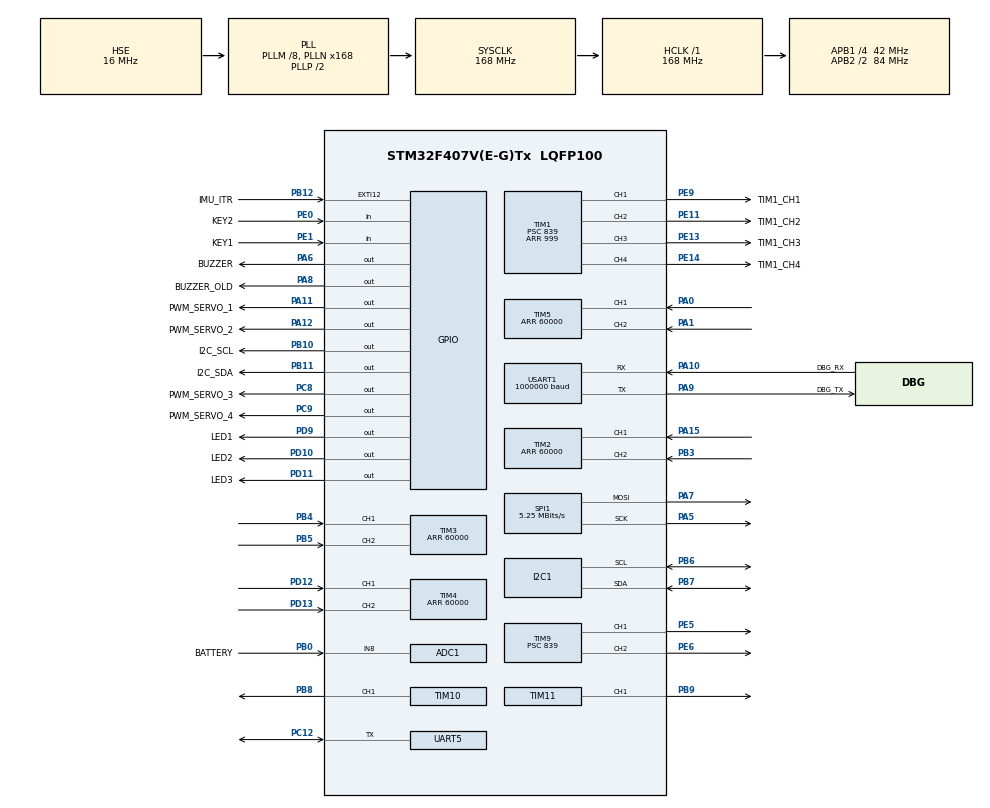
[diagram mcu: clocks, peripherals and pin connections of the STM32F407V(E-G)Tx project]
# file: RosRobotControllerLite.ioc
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ADC1.Channel-4\#ChannelRegularConversion=ADC_CHANNEL_VREFINT
ADC1.Channel-5\#ChannelRegularConversion=ADC_CHANNEL_8
ADC1.ClockPrescaler=ADC_CLOCK_SYNC_PCLK_DIV8
ADC1.ContinuousConvMode=DISABLE
ADC1.EOCSelection=ADC_EOC_SEQ_CONV
ADC1.NbrOfConversion=2
ADC1.NbrOfConversionFlag=1
ADC1.Rank-4\#ChannelRegularConversion=1
ADC1.Rank-5\#ChannelRegularConversion=2
ADC1.SamplingTime-4\#ChannelRegularConversion=ADC_SAMPLETIME_480CYCLES
ADC1.SamplingTime-5\#ChannelRegularConversion=ADC_SAMPLETIME_480CYCLES
ADC1.master=1
Dma.ADC1.0.Direction=DMA_PERIPH_TO_MEMORY
Dma.ADC1.0.FIFOMode=DMA_FIFOMODE_DISABLE
Dma.ADC1.0.Instance=DMA2_Stream0
Dma.ADC1.0.MemDataAlignment=DMA_MDATAALIGN_HALFWORD
Dma.ADC1.0.MemInc=DMA_MINC_ENABLE
Dma.ADC1.0.Mode=DMA_CIRCULAR
Dma.ADC1.0.PeriphDataAlignment=DMA_PDATAALIGN_HALFWORD
Dma.ADC1.0.PeriphInc=DMA_PINC_DISABLE
Dma.ADC1.0.Priority=DMA_PRIORITY_LOW
Dma.Request0=ADC1
Dma.Request1=USART1_RX
Dma.Request2=USART1_TX
Dma.Request3=SPI1_TX
Dma.SPI1_TX.3.Direction=DMA_MEMORY_TO_PERIPH
Dma.SPI1_TX.3.FIFOMode=DMA_FIFOMODE_DISABLE
Dma.SPI1_TX.3.Instance=DMA2_Stream3
Dma.SPI1_TX.3.MemDataAlignment=DMA_MDATAALIGN_BYTE
Dma.SPI1_TX.3.MemInc=DMA_MINC_ENABLE
Dma.SPI1_TX.3.Mode=DMA_NORMAL
Dma.SPI1_TX.3.PeriphDataAlignment=DMA_PDATAALIGN_BYTE
Dma.SPI1_TX.3.PeriphInc=DMA_PINC_DISABLE
Dma.SPI1_TX.3.Priority=DMA_PRIORITY_MEDIUM
Dma.USART1_RX.1.Direction=DMA_PERIPH_TO_MEMORY
Dma.USART1_RX.1.FIFOMode=DMA_FIFOMODE_DISABLE
Dma.USART1_RX.1.Instance=DMA2_Stream2
Dma.USART1_RX.1.MemDataAlignment=DMA_MDATAALIGN_BYTE
Dma.USART1_RX.1.MemInc=DMA_MINC_ENABLE
Dma.USART1_RX.1.Mode=DMA_NORMAL
Dma.USART1_RX.1.PeriphDataAlignment=DMA_PDATAALIGN_BYTE
Dma.USART1_RX.1.PeriphInc=DMA_PINC_DISABLE
Dma.USART1_RX.1.Priority=DMA_PRIORITY_HIGH
Dma.USART1_TX.2.Direction=DMA_MEMORY_TO_PERIPH
Dma.USART1_TX.2.FIFOMode=DMA_FIFOMODE_DISABLE
Dma.USART1_TX.2.Instance=DMA2_Stream7
Dma.USART1_TX.2.MemDataAlignment=DMA_MDATAALIGN_BYTE
Dma.USART1_TX.2.MemInc=DMA_MINC_ENABLE
Dma.USART1_TX.2.Mode=DMA_NORMAL
Dma.USART1_TX.2.PeriphDataAlignment=DMA_PDATAALIGN_BYTE
Dma.USART1_TX.2.PeriphInc=DMA_PINC_DISABLE
Dma.USART1_TX.2.Priority=DMA_PRIORITY_MEDIUM
FREERTOS.BinarySemaphores01=packet_tx_idle,Static,packet_tx_ControlBlock;packet_rx_not_empty,Static,packet_rx_not_emptyControlBlock;mpu6050_data_ready,Static,mpu6050_data_readyControlBlock;spi_tx_finished,Static,spi_tx_finishedControlBlock;serial_servo_rx_complete,Dynamic,NULL
FREERTOS.INCLUDE_vTaskCleanUpResources=1
FREERTOS.INCLUDE_xEventGroupSetBitFromISR=1
FREERTOS.Mutexes01=oled_mutex,Dynamic,NULL
FREERTOS.Queues01=packet_tx_queue,64,void*,0,Static,packet_tx_queueBuffer,packet_tx_queueControlBlock;moving_ctrl_queue,32,char,0,Static,moving_ctrl_queueBuffer,moving_ctrl_queueControlBlock
FREERTOS.Tasks01=defaultTask,16,256,StartDefaultTask,Default,NULL,Dynamic,NULL,NULL;imu_task,32,256,imu_task_entry,As weak,NULL,Dynamic,NULL,NULL;packet_tx_task,24,256,packet_tx_task_entry,As weak,NULL,Dynamic,NULL,NULL;packet_rx_task,24,256,packet_rx_task_entry,As weak,NULL,Dynamic,NULL,NULL;gui_task,8,1500,gui_task_entry,As weak,NULL,Dynamic,NULL,NULL;app_task,24,512,app_task_entry,As weak,NULL,Dynamic,NULL,NULL;oled_task,16,256,oled_task_entry,As weak,NULL,Dynamic,NULL,NULL
FREERTOS.Timers01=button_timer,button_timer_callback,osTimerPeriodic,As weak,NULL,Static,button_timerControlBlock;led_timer,led_timer_callback,osTimerPeriodic,As weak,NULL,Static,led_timerControlBlock;buzzer_timer,buzzer_timer_callback,osTimerPeriodic,As weak,NULL,Static,buzzer_timerControlBlock;battery_check_timer,battery_check_timer_callback,osTimerPeriodic,As weak,NULL,Static,battery_check_timerControlBlock
FREERTOS.configENABLE_FPU=1
FREERTOS.configTIMER_QUEUE_LENGTH=10
FREERTOS.configTIMER_TASK_STACK_DEPTH=6144
FREERTOS.configTOTAL_HEAP_SIZE=20480
FREERTOS.configUSE_IDLE_HOOK=1
FREERTOS.configUSE_NEWLIB_REENTRANT=0
FREERTOS.configUSE_TICK_HOOK=1
IWDG.Prescaler=IWDG_PRESCALER_32
IWDG.Reload=19
Mcu.Family=STM32F4
Mcu.Name=STM32F407V(E-G)Tx
Mcu.Package=LQFP100
NVIC.DMA2_Stream2_IRQn=true\:5\:0\:false\:false\:true\:true\:true\:true\:true
NVIC.DMA2_Stream3_IRQn=true\:5\:0\:false\:false\:true\:true\:true\:true\:true
NVIC.DMA2_Stream7_IRQn=true\:5\:0\:false\:false\:true\:true\:true\:true\:true
NVIC.EXTI15_10_IRQn=true\:5\:0\:false\:true\:true\:3\:true\:true\:false\:true
NVIC.PriorityGroup=NVIC_PRIORITYGROUP_4
NVIC.SPI1_IRQn=true\:5\:0\:false\:false\:true\:true\:true\:true\:true
NVIC.TIM2_IRQn=true\:5\:0\:false\:true\:true\:1\:true\:true\:false\:true
NVIC.TIM3_IRQn=true\:5\:0\:false\:true\:true\:2\:true\:true\:false\:true
NVIC.TIM4_IRQn=true\:5\:0\:false\:false\:true\:true\:true\:false\:true
NVIC.TIM5_IRQn=true\:5\:0\:false\:true\:true\:6\:true\:true\:false\:true
NVIC.TIM7_IRQn=true\:5\:0\:false\:true\:true\:7\:true\:true\:false\:true
NVIC.TIM8_BRK_TIM12_IRQn=true\:5\:0\:false\:true\:true\:4\:true\:true\:false\:true
NVIC.TIM8_TRG_COM_TIM14_IRQn=true\:15\:0\:true\:false\:true\:false\:false\:true\:true
NVIC.TIM8_UP_TIM13_IRQn=true\:5\:0\:false\:true\:true\:5\:true\:true\:false\:true
NVIC.TimeBase=TIM8_TRG_COM_TIM14_IRQn
NVIC.TimeBaseIP=TIM14
NVIC.UART5_IRQn=true\:5\:0\:false\:false\:true\:true\:true\:true\:true
NVIC.USART1_IRQn=true\:5\:0\:true\:false\:true\:true\:true\:true\:true
PA0-WKUP.GPIO_PuPd=GPIO_PULLUP
PA0-WKUP.GPIO_Speed=GPIO_SPEED_FREQ_VERY_HIGH
PA0-WKUP.Signal=S_TIM5_CH1
PA1.GPIO_PuPd=GPIO_PULLUP
PA1.GPIO_Speed=GPIO_SPEED_FREQ_VERY_HIGH
PA1.Signal=S_TIM5_CH2
PA10.GPIO_Label=DBG_RX
PA10.Mode=Asynchronous
PA10.Signal=USART1_RX
PA11.GPIO_Label=PWM_SERVO_1
PA11.GPIO_Speed=GPIO_SPEED_FREQ_HIGH
PA11.PinState=GPIO_PIN_RESET
PA11.Signal=GPIO_Output
PA12.GPIO_Label=PWM_SERVO_2
PA12.GPIO_Speed=GPIO_SPEED_FREQ_HIGH
PA12.Signal=GPIO_Output
PA13.Signal=SYS_JTMS-SWDIO
PA14.Signal=SYS_JTCK-SWCLK
PA15.GPIO_PuPd=GPIO_PULLUP
PA15.GPIO_Speed=GPIO_SPEED_FREQ_VERY_HIGH
PA15.Signal=S_TIM2_CH1_ETR
PA5.GPIO_Speed=GPIO_SPEED_FREQ_MEDIUM
PA5.Mode=TX_Only_Simplex_Unidirect_Master
PA5.Signal=SPI1_SCK
PA6.GPIO_Label=BUZZER
PA6.GPIO_Speed=GPIO_SPEED_FREQ_VERY_HIGH
PA6.PinState=GPIO_PIN_RESET
PA6.Signal=GPIO_Output
PA7.GPIO_PuPd=GPIO_PULLUP
PA7.GPIO_Speed=GPIO_SPEED_FREQ_MEDIUM
PA7.Mode=TX_Only_Simplex_Unidirect_Master
PA7.Signal=SPI1_MOSI
PA8.GPIO_Label=BUZZER_OLD
PA8.GPIO_Speed=GPIO_SPEED_FREQ_VERY_HIGH
PA8.PinState=GPIO_PIN_RESET
PA8.Signal=GPIO_Output
PA9.GPIO_Label=DBG_TX
PA9.Mode=Asynchronous
PA9.Signal=USART1_TX
PB0.GPIO_Label=BATTERY
PB0.Signal=ADCx_IN8
PB10.GPIO_Label=I2C_SCL
PB10.Signal=GPIO_Output
PB11.GPIO_Label=I2C_SDA
PB11.Signal=GPIO_Output
PB12.GPIO_Label=IMU_ITR
PB12.GPIO_ModeDefaultEXTI=GPIO_MODE_IT_RISING
PB12.GPIO_PuPd=GPIO_PULLDOWN
PB12.Signal=GPXTI12
PB3.GPIO_PuPd=GPIO_PULLUP
PB3.GPIO_Speed=GPIO_SPEED_FREQ_VERY_HIGH
PB3.Signal=S_TIM2_CH2
PB4.GPIO_Speed=GPIO_SPEED_FREQ_VERY_HIGH
PB4.Signal=S_TIM3_CH1
PB5.GPIO_Speed=GPIO_SPEED_FREQ_VERY_HIGH
PB5.Signal=S_TIM3_CH2
PB6.GPIO_Pu=GPIO_PULLUP
PB6.Mode=I2C
PB6.Signal=I2C1_SCL
PB7.GPIO_Pu=GPIO_PULLUP
PB7.Mode=I2C
PB7.Signal=I2C1_SDA
PB8.Signal=S_TIM10_CH1
PB9.GPIO_Speed=GPIO_SPEED_FREQ_HIGH
PB9.Signal=S_TIM11_CH1
PC12.Mode=Half_duplex(single_wire_mode)
PC12.Signal=UART5_TX
PC8.GPIO_Label=PWM_SERVO_3
PC8.GPIO_Speed=GPIO_SPEED_FREQ_LOW
PC8.PinState=GPIO_PIN_SET
PC8.Signal=GPIO_Output
PC9.GPIO_Label=PWM_SERVO_4
PC9.GPIO_Speed=GPIO_SPEED_FREQ_HIGH
PC9.Signal=GPIO_Output
PD10.GPIO_Label=LED2
PD10.GPIO_Speed=GPIO_SPEED_FREQ_MEDIUM
PD10.PinState=GPIO_PIN_SET
PD10.Signal=GPIO_Output
PD11.GPIO_Label=LED3
PD11.GPIO_Speed=GPIO_SPEED_FREQ_MEDIUM
PD11.PinState=GPIO_PIN_RESET
PD11.Signal=GPIO_Output
PD12.GPIO_PuPd=GPIO_NOPULL
PD12.GPIO_Speed=GPIO_SPEED_FREQ_VERY_HIGH
PD12.Signal=S_TIM4_CH1
PD13.GPIO_PuPd=GPIO_NOPULL
PD13.GPIO_Speed=GPIO_SPEED_FREQ_VERY_HIGH
PD13.Signal=S_TIM4_CH2
PD9.GPIO_Label=LED1
PD9.GPIO_Speed=GPIO_SPEED_FREQ_MEDIUM
PD9.PinState=GPIO_PIN_SET
PD9.Signal=GPIO_Output
PE0.GPIO_Label=KEY2
PE0.Signal=GPIO_Input
PE1.GPIO_Label=KEY1
PE1.Signal=GPIO_Input
PE11.GPIO_Label=TIM1_CH2
PE11.GPIO_Speed=GPIO_SPEED_FREQ_HIGH
PE11.Signal=S_TIM1_CH2
PE13.GPIO_Label=TIM1_CH3
PE13.GPIO_Speed=GPIO_SPEED_FREQ_HIGH
PE13.Signal=S_TIM1_CH3
PE14.GPIO_Label=TIM1_CH4
PE14.GPIO_Speed=GPIO_SPEED_FREQ_HIGH
PE14.Signal=S_TIM1_CH4
PE5.Signal=S_TIM9_CH1
PE6.Signal=S_TIM9_CH2
PE9.GPIO_Label=TIM1_CH1
PE9.GPIO_Speed=GPIO_SPEED_FREQ_HIGH
PE9.Signal=S_TIM1_CH1
PH0-OSC_IN.Mode=HSE-External-Oscillator
PH0-OSC_IN.Signal=RCC_OSC_IN
PH1-OSC_OUT.Mode=HSE-External-Oscillator
PH1-OSC_OUT.Signal=RCC_OSC_OUT
ProjectManager.HeapSize=0x200
ProjectManager.StackSize=0x600
ProjectManager.TargetToolchain=STM32CubeIDE
RCC.48MHZClocksFreq_Value=48000000
RCC.AHBFreq_Value=168000000
RCC.APB1CLKDivider=RCC_HCLK_DIV4
RCC.APB1Freq_Value=42000000
RCC.APB1TimFreq_Value=84000000
RCC.APB2CLKDivider=RCC_HCLK_DIV2
RCC.APB2Freq_Value=84000000
RCC.APB2TimFreq_Value=168000000
RCC.CortexFreq_Value=168000000
RCC.EnbaleCSS=true
RCC.HCLKFreq_Value=168000000
RCC.HSE_VALUE=16000000
RCC.HSI_VALUE=16000000
RCC.LSE_VALUE=32768
RCC.PLLM=8
RCC.PLLN=168
RCC.PLLQ=7
RCC.PLLSourceVirtual=RCC_PLLSOURCE_HSE
RCC.SYSCLKFreq_VALUE=168000000
RCC.SYSCLKSource=RCC_SYSCLKSOURCE_PLLCLK
RCC.VCOOutputFreq_Value=336000000
SH.ADCx_IN8.0=ADC1_IN8,IN8
SH.S_TIM10_CH1.0=TIM10_CH1,PWM Generation1 CH1
SH.S_TIM11_CH1.0=TIM11_CH1,PWM Generation1 CH1
SH.S_TIM1_CH1.0=TIM1_CH1,PWM Generation1 CH1
SH.S_TIM1_CH2.0=TIM1_CH2,PWM Generation2 CH2
SH.S_TIM1_CH3.0=TIM1_CH3,PWM Generation3 CH3
SH.S_TIM1_CH4.0=TIM1_CH4,PWM Generation4 CH4
SH.S_TIM2_CH1_ETR.0=TIM2_CH1,Encoder_Interface
SH.S_TIM2_CH2.0=TIM2_CH2,Encoder_Interface
SH.S_TIM3_CH1.0=TIM3_CH1,Encoder_Interface
SH.S_TIM3_CH2.0=TIM3_CH2,Encoder_Interface
SH.S_TIM4_CH1.0=TIM4_CH1,Encoder_Interface
SH.S_TIM4_CH2.0=TIM4_CH2,Encoder_Interface
SH.S_TIM5_CH1.0=TIM5_CH1,Encoder_Interface
SH.S_TIM5_CH2.0=TIM5_CH2,Encoder_Interface
SH.S_TIM9_CH1.0=TIM9_CH1,PWM Generation1 CH1
SH.S_TIM9_CH2.0=TIM9_CH2,PWM Generation2 CH2
SPI1.BaudRatePrescaler=SPI_BAUDRATEPRESCALER_16
SPI1.CLKPolarity=SPI_POLARITY_LOW
SPI1.CalculateBaudRate=5.25 MBits/s
SPI1.Direction=SPI_DIRECTION_2LINES
SPI1.Mode=SPI_MODE_MASTER
SPI1.VirtualType=VM_MASTER
TIM1.AutoReloadPreload=TIM_AUTORELOAD_PRELOAD_ENABLE
TIM1.Channel-PWM\ Generation1\ CH1=TIM_CHANNEL_1
TIM1.Channel-PWM\ Generation2\ CH2=TIM_CHANNEL_2
TIM1.Channel-PWM\ Generation3\ CH3=TIM_CHANNEL_3
TIM1.Channel-PWM\ Generation4\ CH4=TIM_CHANNEL_4
TIM1.OCFastMode_PWM-PWM\ Generation1\ CH1=TIM_OCFAST_ENABLE
TIM1.OCFastMode_PWM-PWM\ Generation2\ CH2=TIM_OCFAST_ENABLE
TIM1.OCFastMode_PWM-PWM\ Generation3\ CH3=TIM_OCFAST_ENABLE
TIM1.OCFastMode_PWM-PWM\ Generation4\ CH4=TIM_OCFAST_ENABLE
TIM1.Period=999
TIM1.Prescaler=839
TIM1.Pulse-PWM\ Generation1\ CH1=0
TIM1.Pulse-PWM\ Generation2\ CH2=0
TIM1.Pulse-PWM\ Generation3\ CH3=0
TIM1.Pulse-PWM\ Generation4\ CH4=0
TIM10.AutoReloadPreload=TIM_AUTORELOAD_PRELOAD_ENABLE
TIM10.Channel=TIM_CHANNEL_1
TIM10.OCFastMode_PWM=TIM_OCFAST_ENABLE
TIM10.Period=999
TIM10.Prescaler=839
TIM11.AutoReloadPreload=TIM_AUTORELOAD_PRELOAD_ENABLE
TIM11.Channel=TIM_CHANNEL_1
TIM11.OCFastMode_PWM=TIM_OCFAST_ENABLE
TIM11.Period=999
TIM11.Prescaler=839
TIM11.Pulse=0
TIM12.AutoReloadPreload=TIM_AUTORELOAD_PRELOAD_ENABLE
TIM12.Channel-Output\ Compare1\ No\ Output=TIM_CHANNEL_1
TIM12.OC1Preload=ENABLE
TIM12.OCMode_1=TIM_OCMODE_TIMING
TIM12.Period=99
TIM12.Prescaler=839
TIM12.Pulse-Output\ Compare1\ No\ Output=50
TIM13.AutoReloadPreload=TIM_AUTORELOAD_PRELOAD_DISABLE
TIM13.Channel=TIM_CHANNEL_1
TIM13.OC1Preload=DISABLE
TIM13.Period=4999
TIM13.Prescaler=83
TIM13.Pulse=0
TIM2.AutoReloadPreload=TIM_AUTORELOAD_PRELOAD_ENABLE
TIM2.EncoderMode=TIM_ENCODERMODE_TI12
TIM2.Period=60000
TIM3.AutoReloadPreload=TIM_AUTORELOAD_PRELOAD_ENABLE
TIM3.EncoderMode=TIM_ENCODERMODE_TI12
TIM3.Period=60000
TIM4.AutoReloadPreload=TIM_AUTORELOAD_PRELOAD_ENABLE
TIM4.EncoderMode=TIM_ENCODERMODE_TI12
TIM4.IC1Polarity=TIM_ICPOLARITY_RISING
TIM4.IC2Polarity=TIM_ICPOLARITY_RISING
TIM4.Period=60000
TIM5.AutoReloadPreload=TIM_AUTORELOAD_PRELOAD_ENABLE
TIM5.EncoderMode=TIM_ENCODERMODE_TI12
TIM5.Period=60000
TIM7.AutoReloadPreload=TIM_AUTORELOAD_PRELOAD_ENABLE
TIM7.Period=9999
TIM7.Prescaler=83
TIM9.AutoReloadPreload=TIM_AUTORELOAD_PRELOAD_ENABLE
TIM9.Channel-PWM\ Generation1\ CH1=TIM_CHANNEL_1
TIM9.Channel-PWM\ Generation2\ CH2=TIM_CHANNEL_2
TIM9.OCFastMode_PWM-PWM\ Generation1\ CH1=TIM_OCFAST_ENABLE
TIM9.OCFastMode_PWM-PWM\ Generation2\ CH2=TIM_OCFAST_ENABLE
TIM9.Period=999
TIM9.Prescaler=839
UART5.VirtualMode=Asynchronous
USART1.BaudRate=1000000
USART1.Parity=PARITY_NONE
USART1.VirtualMode=VM_ASYNC
VP_ADC1_Vref_Input.Mode=IN-Vrefint
VP_CRC_VS_CRC.Mode=CRC_Activate
VP_FREERTOS_VS_CMSIS_V2.Mode=CMSIS_V2
VP_IWDG_VS_IWDG.Mode=IWDG_Activate
VP_SYS_VS_tim14.Mode=TIM14
VP_TIM10_VS_ClockSourceINT.Mode=Enable_Timer
VP_TIM11_VS_ClockSourceINT.Mode=Enable_Timer
VP_TIM12_VS_ClockSourceINT.Mode=Internal
VP_TIM12_VS_no_output1.Mode=Output Compare1 No Output
VP_TIM13_VS_ClockSourceINT.Mode=Enable_Timer
VP_TIM13_VS_no_output1.Mode=Output Compare1 No Output
VP_TIM1_VS_ClockSourceINT.Mode=Internal
VP_TIM7_VS_ClockSourceINT.Mode=Enable_Timer
VP_TIM9_VS_ClockSourceINT.Mode=Internal
board=custom

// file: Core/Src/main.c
/* USER CODE BEGIN Header */
/**
  ******************************************************************************
  * @file           : main.c
  * @brief          : Main program body
  ******************************************************************************
  * @attention
  *
  * Copyright (c) 2026 STMicroelectronics.
  * All rights reserved.
  *
  * This software is licensed under terms that can be found in the LICENSE file
  * in the root directory of this software component.
  * If no LICENSE file comes with this software, it is provided AS-IS.
  *
  ******************************************************************************
  */
/* USER CODE END Header */
#include "main.h"
#include "cmsis_os.h"
#include "adc.h"
#include "crc.h"
#include "dma.h"
#include "i2c.h"
#include "iwdg.h"
#include "spi.h"
#include "tim.h"
#include "usart.h"
#include "gpio.h"

void SystemClock_Config(void);
void MX_FREERTOS_Init(void);
static void MX_NVIC_Init(void);

int main(void)
{

  /* MCU Configuration--------------------------------------------------------*/

  /* Reset of all peripherals, Initializes the Flash interface and the Systick. */
  HAL_Init();

  /* Configure the system clock */
  SystemClock_Config();

  /* Initialize all configured peripherals */
  MX_GPIO_Init();
  MX_DMA_Init();
  MX_USART1_UART_Init();
  MX_TIM1_Init();
  MX_TIM2_Init();
  MX_TIM5_Init();
  MX_TIM9_Init();
  MX_TIM10_Init();
  MX_TIM11_Init();
  MX_TIM7_Init();
  MX_TIM3_Init();
  MX_TIM4_Init();
  MX_TIM13_Init();
  MX_CRC_Init();
  MX_TIM12_Init();
  MX_ADC1_Init();
  MX_I2C1_Init();
  MX_UART5_Init();
  MX_SPI1_Init();
  MX_IWDG_Init();

  /* Initialize interrupts */
  MX_NVIC_Init();

  /* Init scheduler */
  osKernelInitialize();  /* Call init function for freertos objects (in freertos.c) */
  MX_FREERTOS_Init();

  /* Start scheduler */
  osKernelStart();
  /* We should never get here as control is now taken by the scheduler */
  /* Infinite loop */
  while (1)
  {

  }
}

void SystemClock_Config(void)
{
  RCC_OscInitTypeDef RCC_OscInitStruct = {0};
  RCC_ClkInitTypeDef RCC_ClkInitStruct = {0};

  /** Configure the main internal regulator output voltage
  */
  __HAL_RCC_PWR_CLK_ENABLE();
  __HAL_PWR_VOLTAGESCALING_CONFIG(PWR_REGULATOR_VOLTAGE_SCALE1);

  /** Initializes the RCC Oscillators according to the specified parameters
  * in the RCC_OscInitTypeDef structure.
  */
  RCC_OscInitStruct.OscillatorType = RCC_OSCILLATORTYPE_LSI|RCC_OSCILLATORTYPE_HSE;
  RCC_OscInitStruct.HSEState = RCC_HSE_ON;
  RCC_OscInitStruct.LSIState = RCC_LSI_ON;
  RCC_OscInitStruct.PLL.PLLState = RCC_PLL_ON;
  RCC_OscInitStruct.PLL.PLLSource = RCC_PLLSOURCE_HSE;
  RCC_OscInitStruct.PLL.PLLM = 8;
  RCC_OscInitStruct.PLL.PLLN = 168;
  RCC_OscInitStruct.PLL.PLLP = RCC_PLLP_DIV2;
  RCC_OscInitStruct.PLL.PLLQ = 7;
  if (HAL_RCC_OscConfig(&RCC_OscInitStruct) != HAL_OK)
  {
    Error_Handler();
  }

  /** Initializes the CPU, AHB and APB buses clocks
  */
  RCC_ClkInitStruct.ClockType = RCC_CLOCKTYPE_HCLK|RCC_CLOCKTYPE_SYSCLK
                              |RCC_CLOCKTYPE_PCLK1|RCC_CLOCKTYPE_PCLK2;
  RCC_ClkInitStruct.SYSCLKSource = RCC_SYSCLKSOURCE_PLLCLK;
  RCC_ClkInitStruct.AHBCLKDivider = RCC_SYSCLK_DIV1;
  RCC_ClkInitStruct.APB1CLKDivider = RCC_HCLK_DIV4;
  RCC_ClkInitStruct.APB2CLKDivider = RCC_HCLK_DIV2;

  if (HAL_RCC_ClockConfig(&RCC_ClkInitStruct, FLASH_LATENCY_5) != HAL_OK)
  {
    Error_Handler();
  }

  /** Enables the Clock Security System
  */
  HAL_RCC_EnableCSS();
}

/**
  * @brief NVIC Configuration.
  * @retval None
  */
static void MX_NVIC_Init(void)
{
  /* TIM2_IRQn interrupt configuration */
  HAL_NVIC_SetPriority(TIM2_IRQn, 5, 0);
  HAL_NVIC_EnableIRQ(TIM2_IRQn);
  /* TIM3_IRQn interrupt configuration */
  HAL_NVIC_SetPriority(TIM3_IRQn, 5, 0);
  HAL_NVIC_EnableIRQ(TIM3_IRQn);
  /* EXTI15_10_IRQn interrupt configuration */
  HAL_NVIC_SetPriority(EXTI15_10_IRQn, 5, 0);
  HAL_NVIC_EnableIRQ(EXTI15_10_IRQn);
  /* TIM8_BRK_TIM12_IRQn interrupt configuration */
  HAL_NVIC_SetPriority(TIM8_BRK_TIM12_IRQn, 5, 0);
  HAL_NVIC_EnableIRQ(TIM8_BRK_TIM12_IRQn);
  /* TIM8_UP_TIM13_IRQn interrupt configuration */
  HAL_NVIC_SetPriority(TIM8_UP_TIM13_IRQn, 5, 0);
  HAL_NVIC_EnableIRQ(TIM8_UP_TIM13_IRQn);
  /* TIM5_IRQn interrupt configuration */
  HAL_NVIC_SetPriority(TIM5_IRQn, 5, 0);
  HAL_NVIC_EnableIRQ(TIM5_IRQn);
  /* TIM7_IRQn interrupt configuration */
  HAL_NVIC_SetPriority(TIM7_IRQn, 5, 0);
  HAL_NVIC_EnableIRQ(TIM7_IRQn);
}

void HAL_TIM_PeriodElapsedCallback(TIM_HandleTypeDef *htim)
{
  if (htim->Instance == TIM14) {
    HAL_IncTick();
  }
}

void Error_Handler(void)
{
  __disable_irq();
  while (1)
  {
  }
}

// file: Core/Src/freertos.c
/* USER CODE BEGIN Header */
/**
  ******************************************************************************
  * File Name          : freertos.c
  * Description        : Code for freertos applications
  ******************************************************************************
  * @attention
  *
  * Copyright (c) 2026 STMicroelectronics.
  * All rights reserved.
  *
  * This software is licensed under terms that can be found in the LICENSE file
  * in the root directory of this software component.
  * If no LICENSE file comes with this software, it is provided AS-IS.
  *
  ******************************************************************************
  */
/* USER CODE END Header */

#include "FreeRTOS.h"
#include "task.h"
#include "main.h"
#include "cmsis_os.h"

typedef StaticQueue_t osStaticMessageQDef_t;
typedef StaticTimer_t osStaticTimerDef_t;

/* Definitions for defaultTask */
osThreadId_t defaultTaskHandle;
const osThreadAttr_t defaultTask_attributes = {
  .name = "defaultTask",
  .stack_size = 256 * 4,
  .priority = (osPriority_t) osPriorityBelowNormal,
};
/* Definitions for imu_task */
osThreadId_t imu_taskHandle;
const osThreadAttr_t imu_task_attributes = {
  .name = "imu_task",
  .stack_size = 256 * 4,
  .priority = (osPriority_t) osPriorityAboveNormal,
};
/* Definitions for packet_tx_task */
osThreadId_t packet_tx_taskHandle;
const osThreadAttr_t packet_tx_task_attributes = {
  .name = "packet_tx_task",
  .stack_size = 256 * 4,
  .priority = (osPriority_t) osPriorityNormal,
};
/* Definitions for packet_rx_task */
osThreadId_t packet_rx_taskHandle;
const osThreadAttr_t packet_rx_task_attributes = {
  .name = "packet_rx_task",
  .stack_size = 256 * 4,
  .priority = (osPriority_t) osPriorityNormal,
};
/* Definitions for gui_task */
osThreadId_t gui_taskHandle;
const osThreadAttr_t gui_task_attributes = {
  .name = "gui_task",
  .stack_size = 1500 * 4,
  .priority = (osPriority_t) osPriorityLow,
};
/* Definitions for app_task */
osThreadId_t app_taskHandle;
const osThreadAttr_t app_task_attributes = {
  .name = "app_task",
  .stack_size = 512 * 4,
  .priority = (osPriority_t) osPriorityNormal,
};
/* Definitions for oled_task */
osThreadId_t oled_taskHandle;
const osThreadAttr_t oled_task_attributes = {
  .name = "oled_task",
  .stack_size = 256 * 4,
  .priority = (osPriority_t) osPriorityBelowNormal,
};
/* Definitions for packet_tx_queue */
osMessageQueueId_t packet_tx_queueHandle;
uint8_t packet_tx_queueBuffer[ 64 * sizeof( void* ) ];
osStaticMessageQDef_t packet_tx_queueControlBlock;
const osMessageQueueAttr_t packet_tx_queue_attributes = {
  .name = "packet_tx_queue",
  .cb_mem = &packet_tx_queueControlBlock,
  .cb_size = sizeof(packet_tx_queueControlBlock),
  .mq_mem = &packet_tx_queueBuffer,
  .mq_size = sizeof(packet_tx_queueBuffer)
};
/* Definitions for moving_ctrl_queue */
osMessageQueueId_t moving_ctrl_queueHandle;
uint8_t moving_ctrl_queueBuffer[ 32 * sizeof( char ) ];
osStaticMessageQDef_t moving_ctrl_queueControlBlock;
const osMessageQueueAttr_t moving_ctrl_queue_attributes = {
  .name = "moving_ctrl_queue",
  .cb_mem = &moving_ctrl_queueControlBlock,
  .cb_size = sizeof(moving_ctrl_queueControlBlock),
  .mq_mem = &moving_ctrl_queueBuffer,
  .mq_size = sizeof(moving_ctrl_queueBuffer)
};
/* Definitions for button_timer */
osTimerId_t button_timerHandle;
osStaticTimerDef_t button_timerControlBlock;
const osTimerAttr_t button_timer_attributes = {
  .name = "button_timer",
  .cb_mem = &button_timerControlBlock,
  .cb_size = sizeof(button_timerControlBlock),
};
/* Definitions for led_timer */
osTimerId_t led_timerHandle;
osStaticTimerDef_t led_timerControlBlock;
const osTimerAttr_t led_timer_attributes = {
  .name = "led_timer",
  .cb_mem = &led_timerControlBlock,
  .cb_size = sizeof(led_timerControlBlock),
};
/* Definitions for buzzer_timer */
osTimerId_t buzzer_timerHandle;
osStaticTimerDef_t buzzer_timerControlBlock;
const osTimerAttr_t buzzer_timer_attributes = {
  .name = "buzzer_timer",
  .cb_mem = &buzzer_timerControlBlock,
  .cb_size = sizeof(buzzer_timerControlBlock),
};
/* Definitions for battery_check_timer */
osTimerId_t battery_check_timerHandle;
osStaticTimerDef_t battery_check_timerControlBlock;
const osTimerAttr_t battery_check_timer_attributes = {
  .name = "battery_check_timer",
  .cb_mem = &battery_check_timerControlBlock,
  .cb_size = sizeof(battery_check_timerControlBlock),
};
/* Definitions for oled_mutex */
osMutexId_t oled_mutexHandle;
const osMutexAttr_t oled_mutex_attributes = {
  .name = "oled_mutex"
};
/* Definitions for packet_tx_idle */
osSemaphoreId_t packet_tx_idleHandle;
const osSemaphoreAttr_t packet_tx_idle_attributes = {
  .name = "packet_tx_idle"
};
/* Definitions for packet_rx_not_empty */
osSemaphoreId_t packet_rx_not_emptyHandle;
const osSemaphoreAttr_t packet_rx_not_empty_attributes = {
  .name = "packet_rx_not_empty"
};
/* Definitions for mpu6050_data_ready */
osSemaphoreId_t mpu6050_data_readyHandle;
const osSemaphoreAttr_t mpu6050_data_ready_attributes = {
  .name = "mpu6050_data_ready"
};
/* Definitions for spi_tx_finished */
osSemaphoreId_t spi_tx_finishedHandle;
const osSemaphoreAttr_t spi_tx_finished_attributes = {
  .name = "spi_tx_finished"
};
/* Definitions for serial_servo_rx_complete */
osSemaphoreId_t serial_servo_rx_completeHandle;
const osSemaphoreAttr_t serial_servo_rx_complete_attributes = {
  .name = "serial_servo_rx_complete"
};

void StartDefaultTask(void *argument);
void imu_task_entry(void *argument);
void packet_tx_task_entry(void *argument);
void packet_rx_task_entry(void *argument);
void gui_task_entry(void *argument);
void app_task_entry(void *argument);
void oled_task_entry(void *argument);
void button_timer_callback(void *argument);
void led_timer_callback(void *argument);
void buzzer_timer_callback(void *argument);
void battery_check_timer_callback(void *argument);

void MX_FREERTOS_Init(void); /* (MISRA C 2004 rule 8.1) */

/* Hook prototypes */
void vApplicationIdleHook(void);
void vApplicationTickHook(void);

/* USER CODE BEGIN 2 */
void vApplicationIdleHook( void )
{
   /* vApplicationIdleHook() will only be called if configUSE_IDLE_HOOK is set
   to 1 in FreeRTOSConfig.h. It will be called on each iteration of the idle
   task. It is essential that code added to this hook function never attempts
   to block in any way (for example, call xQueueReceive() with a block time
   specified, or call vTaskDelay()). If the application makes use of the
   vTaskDelete() API function (as this demo application does) then it is also
   important that vApplicationIdleHook() is permitted to return to its calling
   function, because it is the responsibility of the idle task to clean up
   memory allocated by the kernel to any task that has since been deleted. */
}
/* USER CODE END 2 */

/* USER CODE BEGIN 3 */
void vApplicationTickHook( void )
{
   /* This function will be called by each tick interrupt if
   configUSE_TICK_HOOK is set to 1 in FreeRTOSConfig.h. User code can be
   added here, but the tick hook is called from an interrupt context, so
   code must not attempt to block, and only the interrupt safe FreeRTOS API
   functions can be used (those that end in FromISR()). */
}
/* USER CODE END 3 */

void MX_FREERTOS_Init(void) {
  /* Create the mutex(es) */
  /* creation of oled_mutex */
  oled_mutexHandle = osMutexNew(&oled_mutex_attributes);

  /* Create the semaphores(s) */
  /* creation of packet_tx_idle */
  packet_tx_idleHandle = osSemaphoreNew(1, 1, &packet_tx_idle_attributes);

  /* creation of packet_rx_not_empty */
  packet_rx_not_emptyHandle = osSemaphoreNew(1, 1, &packet_rx_not_empty_attributes);

  /* creation of mpu6050_data_ready */
  mpu6050_data_readyHandle = osSemaphoreNew(1, 1, &mpu6050_data_ready_attributes);

  /* creation of spi_tx_finished */
  spi_tx_finishedHandle = osSemaphoreNew(1, 1, &spi_tx_finished_attributes);

  /* creation of serial_servo_rx_complete */
  serial_servo_rx_completeHandle = osSemaphoreNew(1, 1, &serial_servo_rx_complete_attributes);

  /* Create the timer(s) */
  /* creation of button_timer */
  button_timerHandle = osTimerNew(button_timer_callback, osTimerPeriodic, NULL, &button_timer_attributes);

  /* creation of led_timer */
  led_timerHandle = osTimerNew(led_timer_callback, osTimerPeriodic, NULL, &led_timer_attributes);

  /* creation of buzzer_timer */
  buzzer_timerHandle = osTimerNew(buzzer_timer_callback, osTimerPeriodic, NULL, &buzzer_timer_attributes);

  /* creation of battery_check_timer */
  battery_check_timerHandle = osTimerNew(battery_check_timer_callback, osTimerPeriodic, NULL, &battery_check_timer_attributes);

  /* Create the queue(s) */
  /* creation of packet_tx_queue */
  packet_tx_queueHandle = osMessageQueueNew (64, sizeof(void*), &packet_tx_queue_attributes);

  /* creation of moving_ctrl_queue */
  moving_ctrl_queueHandle = osMessageQueueNew (32, sizeof(char), &moving_ctrl_queue_attributes);

  /* Create the thread(s) */
  /* creation of defaultTask */
  defaultTaskHandle = osThreadNew(StartDefaultTask, NULL, &defaultTask_attributes);

  /* creation of imu_task */
  imu_taskHandle = osThreadNew(imu_task_entry, NULL, &imu_task_attributes);

  /* creation of packet_tx_task */
  packet_tx_taskHandle = osThreadNew(packet_tx_task_entry, NULL, &packet_tx_task_attributes);

  /* creation of packet_rx_task */
  packet_rx_taskHandle = osThreadNew(packet_rx_task_entry, NULL, &packet_rx_task_attributes);

  /* creation of gui_task */
  gui_taskHandle = osThreadNew(gui_task_entry, NULL, &gui_task_attributes);

  /* creation of app_task */
  app_taskHandle = osThreadNew(app_task_entry, NULL, &app_task_attributes);

  /* creation of oled_task */
  oled_taskHandle = osThreadNew(oled_task_entry, NULL, &oled_task_attributes);

}

void StartDefaultTask(void *argument)
{
  for(;;)
  {
    osDelay(1);
  }
}

__weak void imu_task_entry(void *argument)
{
  for(;;)
  {
    osDelay(1);
  }
}

__weak void packet_tx_task_entry(void *argument)
{
  for(;;)
  {
    osDelay(1);
  }
}

__weak void packet_rx_task_entry(void *argument)
{
  for(;;)
  {
    osDelay(1);
  }
}

__weak void gui_task_entry(void *argument)
{
  for(;;)
  {
    osDelay(1);
  }
}

__weak void app_task_entry(void *argument)
{
  for(;;)
  {
    osDelay(1);
  }
}

__weak void oled_task_entry(void *argument)
{
  for(;;)
  {
    osDelay(1);
  }
}

/* button_timer_callback function */
__weak void button_timer_callback(void *argument)
{
}

/* led_timer_callback function */
__weak void led_timer_callback(void *argument)
{
}

/* buzzer_timer_callback function */
__weak void buzzer_timer_callback(void *argument)
{
}

/* battery_check_timer_callback function */
__weak void battery_check_timer_callback(void *argument)
{
}
